# EFR32FG23B010F512IM48 register map
Vendor: Silicon Labs; Series: EFR32; File version: C
CPU: CM33 r0p4, little endian, MPU, FPU, DSP, VTOR, 4 interrupt priority bits, 8 SAU regions
Registers are 32-bit, read-write, reset 0x0 unless marked. A register's access mark holds for its fields unless they carry their own. Offsets are from the block's base; [hi:lo] are bit positions; {n}, {i} and the like mark numbered series; 'fields as' and 'values as' point back to an identical list.

## CMU_NS — CMU_NS Registers
Base 0x50008000
Same registers: CMU_S 0x40008000
0x00 IPVERSION ro reset 0x2
  [31:0] IPVERSION — IP Version ID
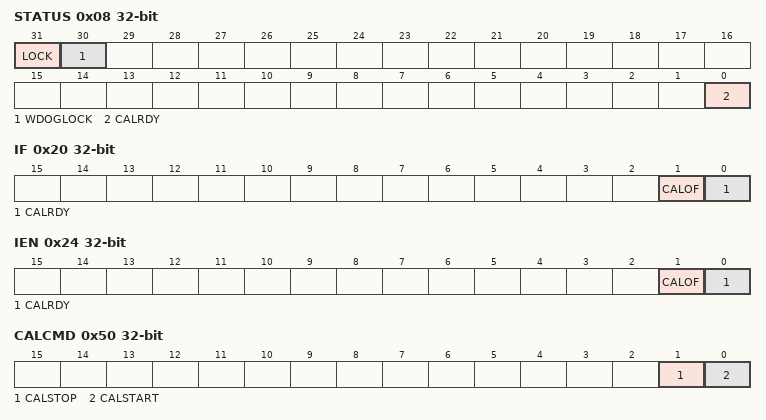
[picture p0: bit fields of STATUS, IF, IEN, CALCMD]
0x08 STATUS ro
  [31] LOCK — Configuration Lock Status
    0=UNLOCKED (Configuration lock is unlocked); 1=LOCKED (Configuration lock is locked)
  [30] WDOGLOCK — Configuration Lock Status for WDOG
    0=UNLOCKED (WDOG configuration lock is unlocked); 1=LOCKED (WDOG configuration lock is locked)
  [0] CALRDY — Calibration Ready
0x10 LOCK wo reset 0x93F7
  [15:0] LOCKKEY — Configuration Lock Key
    0x93F7=UNLOCK (Write this value to unlock)
0x14 WDOGLOCK wo reset 0x5257
  fields as LOCK
0x20 IF
  [1] CALOF — Calibration Overflow Interrupt Flag
  [0] CALRDY — Calibration Ready Interrupt Flag
0x24 IEN
  [1] CALOF — Calibration Overflow Interrupt Enable
  [0] CALRDY — Calibration Ready Interrupt Enable
0x50 CALCMD wo
  [1] CALSTOP — Calibration Stop
  [0] CALSTART — Calibration Start
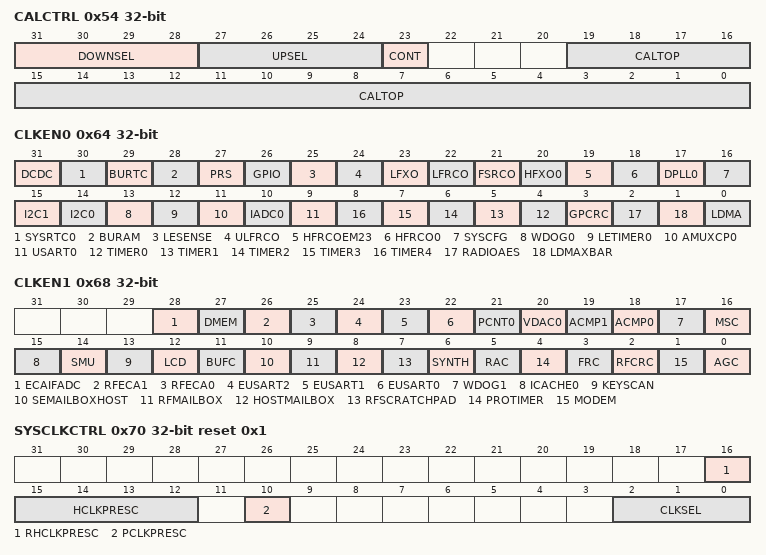
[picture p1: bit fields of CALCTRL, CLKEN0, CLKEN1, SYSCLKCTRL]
0x54 CALCTRL
  [31:28] DOWNSEL — Calibration Down-counter Select
    0=DISABLED (Down-counter is not clocked); 1=HCLK (HCLK is clocking down-counter); 2=PRS (PRS CMU_CALDN consumer is clocking down-counter); 3=HFXO (HFXO is clocking down-counter); 4=LFXO (LFXO is clocking down-counter); 5=HFRCODPLL (HFRCODPLL is clocking down-counter); 6=HFRCOEM23 (HFRCOEM23 is clocking down-counter); 9=FSRCO (FSRCO is clocking down-counter); 10=LFRCO (LFRCO is clocking down-counter); 11=ULFRCO (ULFRCO is clocking down-counter)
  [27:24] UPSEL — Calibration Up-counter Select
    0=DISABLED (Up-counter is not clocked); 1=PRS (PRS CMU_CALUP consumer is clocking up-counter); 2=HFXO (HFXO is clocking up-counter); 3=LFXO (LFXO is clocking up-counter); 4=HFRCODPLL (HFRCODPLL is clocking up-counter); 5=HFRCOEM23 (HFRCOEM23 is clocking up-counter); 8=FSRCO (FSRCO is clocking up-counter); 9=LFRCO (LFRCO is clocking up-counter); 10=ULFRCO (ULFRCO is clocking up-counter)
  [23] CONT — Continuous Calibration
  [19:0] CALTOP — Calibration Counter Top Value
0x58 CALCNT ro
  [19:0] CALCNT — Calibration Result Counter Value
0x64 CLKEN0
  [31] DCDC — Enable Bus Clock
  [30] SYSRTC0 — Enable Bus Clock
  [29] BURTC — Enable Bus Clock
  [28] BURAM — Enable Bus Clock
  [27] PRS — Enable Bus Clock
  [26] GPIO — Enable Bus Clock
  [25] LESENSE — Enable Bus Clock
  [24] ULFRCO — Enable Bus Clock
  [23] LFXO — Enable Bus Clock
  [22] LFRCO — Enable Bus Clock
  [21] FSRCO — Enable Bus Clock
  [20] HFXO0 — Enable Bus Clock
  [19] HFRCOEM23 — Enable Bus Clock
  [18] HFRCO0 — Enable Bus Clock
  [17] DPLL0 — Enable Bus Clock
  [16] SYSCFG — Enable Bus Clock
  [15] I2C1 — Enable Bus Clock
  [14] I2C0 — Enable Bus Clock
  [13] WDOG0 — Enable Bus Clock
  [12] LETIMER0 — Enable Bus Clock
  [11] AMUXCP0 — Enable Bus Clock
  [10] IADC0 — Enable Bus Clock
  [9] USART0 — Enable Bus Clock
  [n+4] TIMER{n} (n=0..4) — Enable Bus Clock
  [3] GPCRC — Enable Bus Clock
  [2] RADIOAES — Enable Bus Clock
  [1] LDMAXBAR — Enable Bus Clock
  [0] LDMA — Enable Bus Clock
0x68 CLKEN1
  [28] ECAIFADC — Enable Bus Clock
  [27] DMEM — Enable Bus Clock
  [26] RFECA1 — Enable Bus Clock
  [25] RFECA0 — Enable Bus Clock
  [24] EUSART2 — Enable Bus Clock
  [23] EUSART1 — Enable Bus Clock
  [22] EUSART0 — Enable Bus Clock
  [21] PCNT0 — Enable Bus Clock
  [20] VDAC0 — Enable Bus Clock
  [19] ACMP1 — Enable Bus Clock
  [18] ACMP0 — Enable Bus Clock
  [17] WDOG1 — Enable Bus Clock
  [16] MSC — Enable Bus Clock
  [15] ICACHE0 — Enable Bus Clock
  [14] SMU — Enable Bus Clock
  [13] KEYSCAN — Enable Bus Clock
  [12] LCD — Enable Bus Clock
  [11] BUFC — Enable Bus Clock
  [10] SEMAILBOXHOST — Enable Bus Clock
  [9] RFMAILBOX — Enable Bus Clock
  [8] HOSTMAILBOX — Enable Bus Clock
  [7] RFSCRATCHPAD — Enable Bus Clock
  [6] SYNTH — Enable Bus Clock
  [5] RAC — Enable Bus Clock
  [4] PROTIMER — Enable Bus Clock
  [3] FRC — Enable Bus Clock
  [2] RFCRC — Enable Bus Clock
  [1] MODEM — Enable Bus Clock
  [0] AGC — Enable Bus Clock
0x70 SYSCLKCTRL reset 0x1
  [16] RHCLKPRESC — Radio HCLK Prescaler
    0=DIV1 (Radio HCLK is SYSCLK divided by 1); 1=DIV2 (Radio HCLK is SYSCLK divided by 2)
  [15:12] HCLKPRESC — HCLK Prescaler
    0=DIV1 (HCLK is SYSCLK divided by 1); 1=DIV2 (HCLK is SYSCLK divided by 2); 3=DIV4 (HCLK is SYSCLK divided by 4); 7=DIV8 (HCLK is SYSCLK divided by 8); 15=DIV16 (HCLK is SYSCLK divided by 16)
  [10] PCLKPRESC — PCLK Prescaler
    0=DIV1 (PCLK is HCLK divided by 1); 1=DIV2 (PCLK is HCLK divided by 2)
  [2:0] CLKSEL — Clock Select
    1=FSRCO (FSRCO is clocking SYSCLK); 2=HFRCODPLL (HFRCODPLL is clocking SYSCLK); 3=HFXO (HFXO is clocking SYSCLK); 4=CLKIN0 (CLKIN0 is clocking SYSCLK)
0x80 TRACECLKCTRL
  [5:4] PRESC — TRACECLK Prescaler
    0=DIV1 (TRACECLK is SYSCLK divided by 1); 1=DIV2 (TRACECLK is SYSCLK divided by 2); 3=DIV4 (TRACECLK is SYSCLK divided by 4)
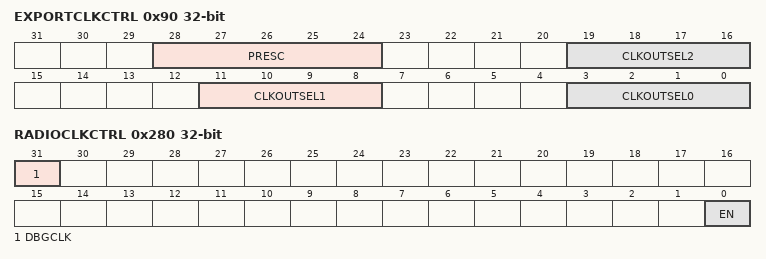
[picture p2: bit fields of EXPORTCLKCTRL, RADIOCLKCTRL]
0x90 EXPORTCLKCTRL
  [28:24] PRESC — EXPORTCLK Prescaler
  [19:16] CLKOUTSEL2 — Clock Output Select 2
    0=DISABLED (CLKOUT2 is not clocked); 1=HCLK (HCLK is clocking CLKOUT2); 2=HFEXPCLK (EXPORTCLK is clocking CLKOUT2); 3=ULFRCO (ULFRCO is clocking CLKOUT2); 4=LFRCO (LFRCO is clocking CLKOUT2); 5=LFXO (LFXO is clocking CLKOUT2); 6=HFRCODPLL (HFRCODPLL is clocking CLKOUT2); 7=HFXO (HFXO is clocking CLKOUT2); 8=FSRCO (FSRCO is clocking CLKOUT2); 9=HFRCOEM23 (HFRCOEM23 is clocking CLKOUT2)
  [11:8] CLKOUTSEL1 — Clock Output Select 1
    0=DISABLED (CLKOUT1 is not clocked); 1=HCLK (HCLK is clocking CLKOUT1); 2=HFEXPCLK (EXPORTCLK is clocking CLKOUT1); 3=ULFRCO (ULFRCO is clocking CLKOUT1); 4=LFRCO (LFRCO is clocking CLKOUT1); 5=LFXO (LFXO is clocking CLKOUT1); 6=HFRCODPLL (HFRCODPLL is clocking CLKOUT1); 7=HFXO (HFXO is clocking CLKOUT1); 8=FSRCO (FSRCO is clocking CLKOUT1); 9=HFRCOEM23 (HFRCOEM23 is clocking CLKOUT1)
  [3:0] CLKOUTSEL0 — Clock Output Select 0
    0=DISABLED (CLKOUT0 is not clocked); 1=HCLK (HCLK is clocking CLKOUT0); 2=HFEXPCLK (EXPORTCLK is clocking CLKOUT0); 3=ULFRCO (ULFRCO is clocking CLKOUT0); 4=LFRCO (LFRCO is clocking CLKOUT0); 5=LFXO (LFXO is clocking CLKOUT0); 6=HFRCODPLL (HFRCODPLL is clocking CLKOUT0); 7=HFXO (HFXO is clocking CLKOUT0); 8=FSRCO (FSRCO is clocking CLKOUT0); 9=HFRCOEM23 (HFRCOEM23 is clocking CLKOUT0)
0x100 DPLLREFCLKCTRL
  [1:0] CLKSEL — Clock Select
    0=DISABLED (DPLLREFCLK is not clocked); 1=HFXO (HFXO is clocking DPLLREFCLK); 2=LFXO (LFXO is clocking DPLLREFCLK); 3=CLKIN0 (CLKIN0 is clocking DPLLREFCLK)
0x120 EM01GRPACLKCTRL reset 0x1
  [2:0] CLKSEL — Clock Select
    1=HFRCODPLL (HFRCODPLL is clocking EM01GRPACLK); 2=HFXO (HFXO is clocking EM01GRPACLK); 3=FSRCO (FSRCO is clocking EM01GRPACLK); 4=HFRCOEM23 (HFRCOEM23 is clocking EM01GRPACLK); 5=HFRCODPLLRT (HFRCODPLL (retimed) is clocking EM01GRPACLK. Check with datasheet for frequency limitation when using retiming with voltage scaling.); 6=HFXORT (HFXO (retimed) is clocking EM01GRPACLK. Check with datasheet for frequency limitation when using retiming with voltage scaling.)
0x128 EM01GRPCCLKCTRL reset 0x1
  [2:0] CLKSEL — Clock Select
    1=HFRCODPLL (HFRCODPLL is clocking EM01GRPCCLK); 2=HFXO (HFXO is clocking EM01GRPCCLK); 3=FSRCO (FSRCO is clocking EM01GRPCCLK); 4=HFRCOEM23 (HFRCOEM23 is clocking EM01GRPCCLK); 5=HFRCODPLLRT (HFRCODPLL (retimed) is clocking EM01GRPCCLK. Check with datasheet for frequency limitation when using retiming with voltage scaling.); 6=HFXORT (HFXO (retimed) is clocking EM01GRPCCLK. Check with datasheet for frequency limitation when using retiming with voltage scaling.)
0x140 EM23GRPACLKCTRL reset 0x1
  [1:0] CLKSEL — Clock Select
    1=LFRCO (LFRCO is clocking EM23GRPACLK); 2=LFXO (LFXO is clocking EM23GRPACLK); 3=ULFRCO (ULFRCO is clocking EM23GRPACLK)
0x160 EM4GRPACLKCTRL reset 0x1
  [1:0] CLKSEL — Clock Select
    1=LFRCO (LFRCO is clocking EM4GRPACLK); 2=LFXO (LFXO is clocking EM4GRPACLK); 3=ULFRCO (ULFRCO is clocking EM4GRPACLK)
0x180 IADCCLKCTRL reset 0x1
  [1:0] CLKSEL — Clock Select
    1=EM01GRPACLK (EM01GRPACLK is clocking IADCCLK); 2=FSRCO (FSRCO is clocking IADCCLK); 3=HFRCOEM23 (HFRCOEM23 is clocking IADCCLK)
0x200 WDOG0CLKCTRL reset 0x1
  [2:0] CLKSEL — Clock Select
    1=LFRCO (LFRCO is clocking WDOG0CLK); 2=LFXO (LFXO is clocking WDOG0CLK); 3=ULFRCO (ULFRCO is clocking WDOG0CLK); 4=HCLKDIV1024 (HCLKDIV1024 is clocking WDOG0CLK)
0x208 WDOG1CLKCTRL reset 0x1
  fields as WDOG0CLKCTRL
0x220 EUSART0CLKCTRL reset 0x1
  [2:0] CLKSEL — Clock Select
    0=DISABLED (EUSART0 is not clocked); 1=EM01GRPCCLK (EM01GRPCCLK is clocking EUSART0); 2=HFRCOEM23 (HFRCOEM23 is clocking EUSART0); 3=LFRCO (LFRCO is clocking EUSART0); 4=LFXO (LFXO is clocking EUSART0)
0x240 SYSRTC0CLKCTRL reset 0x1
  [1:0] CLKSEL — Clock Select
    1=LFRCO (LFRCO is clocking SYSRTC0CLK); 2=LFXO (LFXO is clocking SYSRTC0CLK); 3=ULFRCO (ULFRCO is clocking SYSRTC0CLK)
0x250 LCDCLKCTRL reset 0x1
  [1:0] CLKSEL — Clock Select
    1=LFRCO (LFRCO is clocking LCDCLK); 2=LFXO (LFXO is clocking LCDCLK); 3=ULFRCO (ULFRCO is clocking LCDCLK)
0x260 VDAC0CLKCTRL reset 0x1
  [2:0] CLKSEL — Clock Select
    0=DISABLED (VDAC is not clocked); 1=EM01GRPACLK (EM01GRPACLK is clocking VDAC); 2=EM23GRPACLK (EM23GRPACLK is clocking VDAC); 3=FSRCO (FSRCO is clocking VDAC); 4=HFRCOEM23 (HFRCOEM23 is clocking VDAC)
0x270 PCNT0CLKCTRL reset 0x1
  [1:0] CLKSEL — Clock Select
    0=DISABLED (PCNT0 is not clocked); 1=EM23GRPACLK (EM23GRPACLK is clocking PCNT0); 2=PCNTS0 (External pin PCNT_S0 is clocking PCNT0)
0x280 RADIOCLKCTRL
  [31] DBGCLK — Enable Clock for Debugger
  [0] EN — Enable
0x290 LESENSEHFCLKCTRL reset 0x1
  [1:0] CLKSEL — Clock Select
    1=FSRCO (FSRCO is clocking LESENSEHFCLK); 2=HFRCOEM23 (HFRCOEM23 is clocking LESENSEHFCLK)
